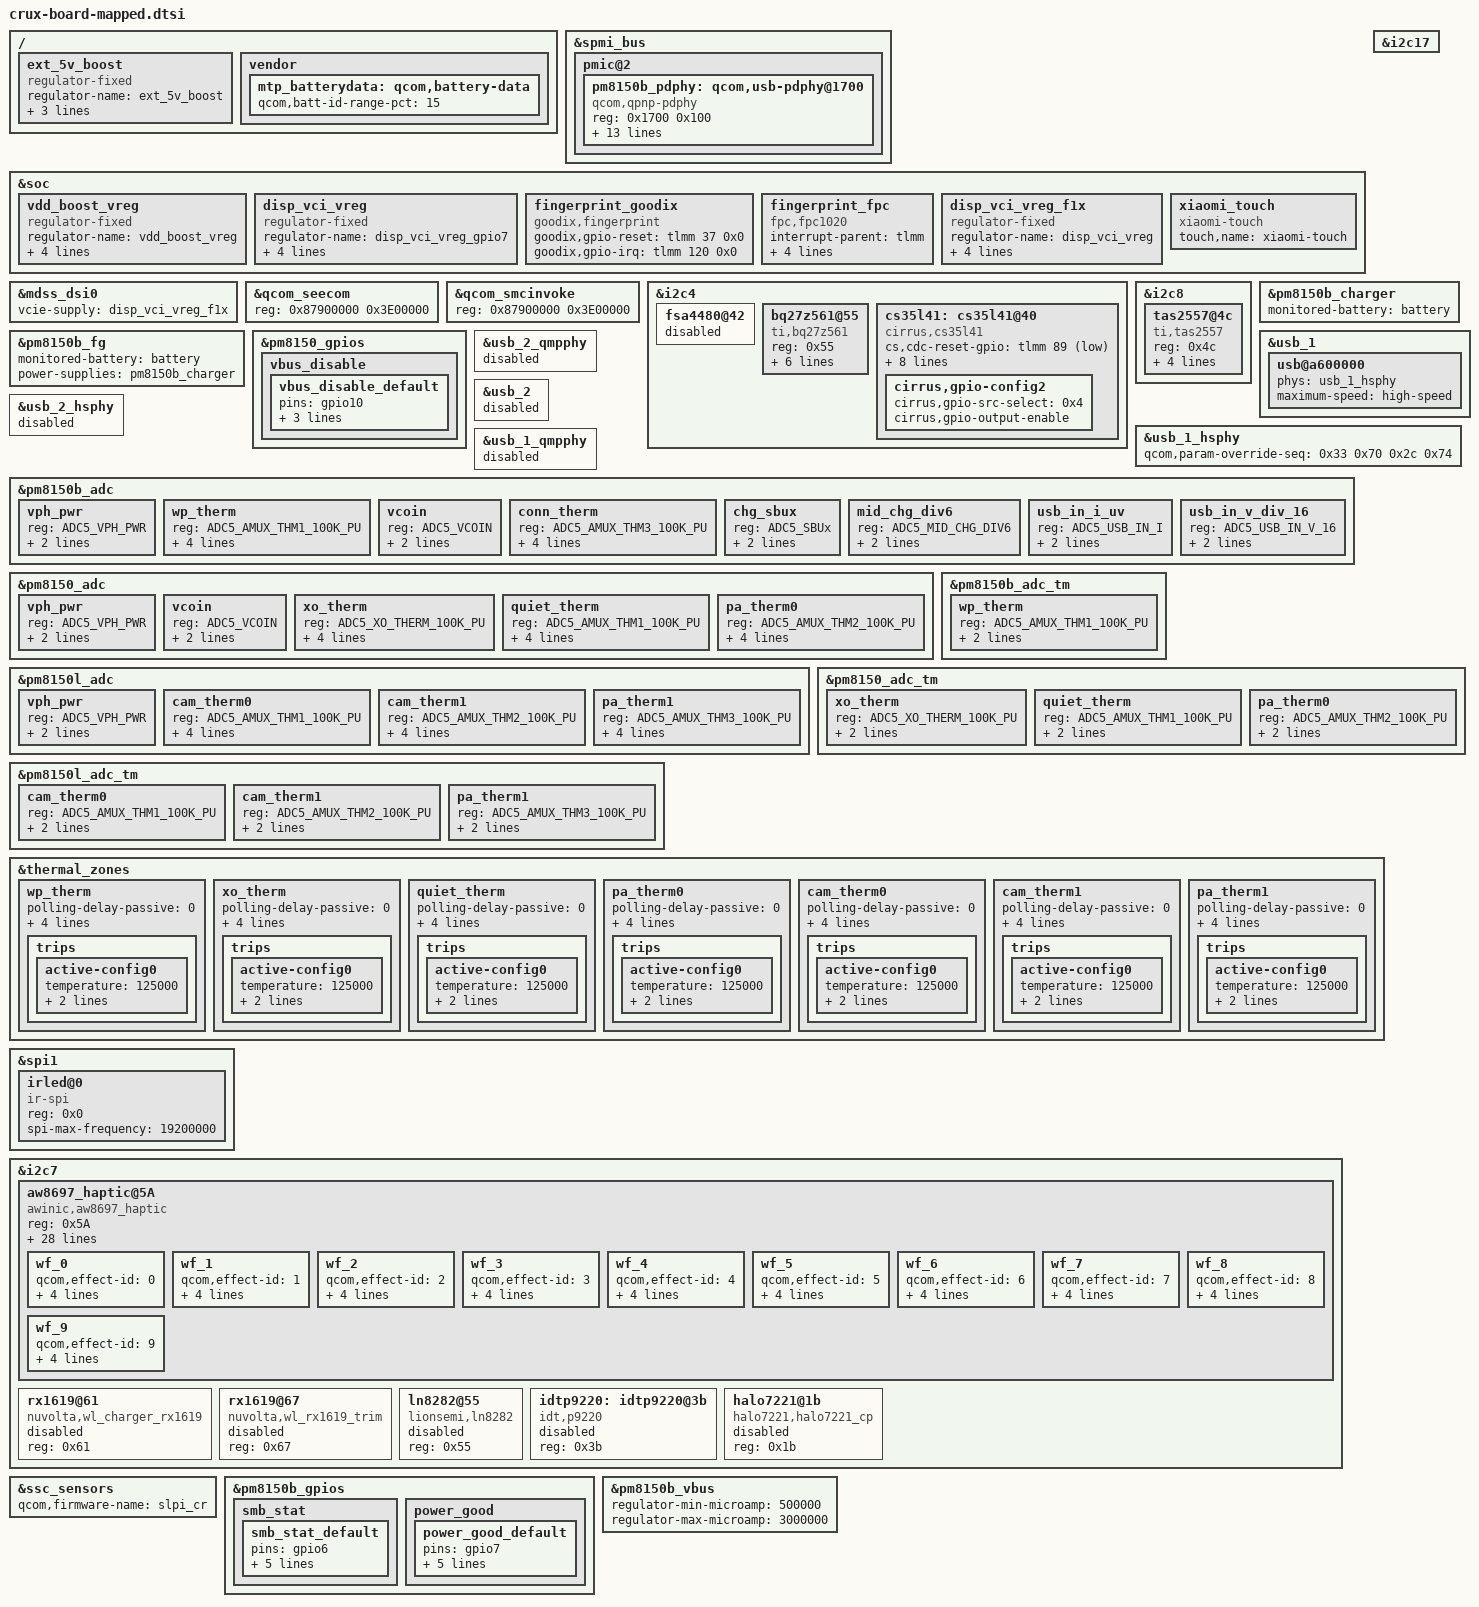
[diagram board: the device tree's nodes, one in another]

&spmi_bus {
	pmic@2 {
		pm8150b_pdphy: qcom,usb-pdphy@1700 {
		compatible = "qcom,qpnp-pdphy";
		reg = <0x1700 0x100>;
		vdd-pdphy-supply = <&vreg_l2a_3p1>;
		vbus-supply = <&pm8150b_vbus>;
		interrupts = <0x2 0x17 0x0 IRQ_TYPE_EDGE_RISING>,
			     <0x2 0x17 0x1 IRQ_TYPE_EDGE_RISING>,
			     <0x2 0x17 0x2 IRQ_TYPE_EDGE_RISING>,
			     <0x2 0x17 0x3 IRQ_TYPE_EDGE_RISING>,
			     <0x2 0x17 0x4 IRQ_TYPE_EDGE_RISING>,
			     <0x2 0x17 0x5 IRQ_TYPE_EDGE_RISING>,
			     <0x2 0x17 0x6 IRQ_TYPE_EDGE_RISING>,
			     <0x2 0x17 0x7 IRQ_TYPE_EDGE_RISING>;
		interrupt-names = "sig-tx",
				  "sig-rx",
				  "msg-tx",
				  "msg-rx",
				  "msg-tx-failed",
				  "msg-tx-discarded",
				  "msg-rx-discarded",
				  "fr-swap";
		qcom,default-sink-caps = <5000 3000>;
	};
};
};

/ {
	ext_5v_boost: ext_5v_boost {
		compatible = "regulator-fixed";
		regulator-name = "ext_5v_boost";
		gpio = <&pm8150b_gpios 12 GPIO_ACTIVE_HIGH>;
		enable-active-high;
		regulator-enable-ramp-delay = <1600>;
		status = "disabled";
	};
};




&soc {
	
	vdd_boost_vreg: vdd_boost_vreg {
		compatible = "regulator-fixed";
		regulator-name = "vdd_boost_vreg";
		startup-delay-us = <4000>;
		enable-active-high;
		regulator-always-on;
		gpio = <&pm8150b_gpios 5 0>;
	 };
	disp_vci_vreg: disp_vci_vreg {
		compatible = "regulator-fixed";
		regulator-name = "disp_vci_vreg_gpio7";
		start-delay-us = <4000>;
		enable-active-high;
		regulator-boot-on;
		gpio = <&tlmm 7 0>;
	};

	
	fingerprint_goodix {
		compatible = "goodix,fingerprint";
		goodix,gpio-reset = <&tlmm 37 0x0>;
		goodix,gpio-irq = <&tlmm 120 0x0>;
		/* fp-gpio-pwr = <&tlmm 125 0>; */
		status = "ok";
	};
	
	fingerprint_fpc {
		status = "ok";
		compatible = "fpc,fpc1020";
		interrupt-parent = <&tlmm>;
		interrupts = <118 0x0>;
		fpc,gpio_irq = <&tlmm 118 0x0>;
		/* fpc,enable-on-boot; */
		/* fpc,enable-wakeup;  */

		pinctrl-names = "fpc1020_reset_reset",
			"fpc1020_reset_active";

		pinctrl-0 = <&msm_gpio_119>;
		pinctrl-1 = <&msm_gpio_119_output_high>;
	};

	disp_vci_vreg_f1x: disp_vci_vreg_f1x {
		compatible = "regulator-fixed";
		regulator-name = "disp_vci_vreg";
		start-delay-us = <4000>;
		enable-active-high;
		regulator-boot-on;
		gpio = <&tlmm 21 0>;
	};
	xiaomi_touch {
		compatible = "xiaomi-touch";
		status = "ok";
		touch,name = "xiaomi-touch";
	};
	
};

&mdss_dsi0 {
	vcie-supply = <&disp_vci_vreg_f1x>;
};













&qcom_seecom {
	reg = <0x87900000 0x3E00000>;
};

&qcom_smcinvoke {
	reg = <0x87900000 0x3E00000>;
};

&i2c4 {
	status = "ok";

	fsa4480@42 {
		status = "disabled";
	};
};

&i2c8 {
	status = "ok";
	/*smart PA*/
	tas2557@4c{
		compatible = "ti,tas2557";
		reg = <0x4c>;
		ti,cdc-reset-gpio = <&tlmm 59 0>;
		ti,irq-gpio = <&tlmm 115 0>;
		ti,i2s-bits = <16>;
		ti,bypass-tmax = <0>;
	};
};

&i2c17 {
	status = "ok";
};

&pm8150b_fg {
	status = "okay";
	monitored-battery = <&battery>;
	power-supplies = <&pm8150b_charger>;
};

/ {
	vendor: vendor {

	mtp_batterydata: qcom,battery-data {
		qcom,batt-id-range-pct = <15>;
	};
	};
};


&pm8150_gpios {
	vbus_disable {
		vbus_disable_default: vbus_disable_default {
			pins = "gpio10";
			function = "normal";
			output-low;
			power-source = <1>;	/* 1.8V input supply */
		};
	};
};

&pm8150b_charger {
	status = "okay";
	monitored-battery = <&battery>;
};












&pm8150b_pdphy {
	vbus-supply = <&ext_5v_boost>;
	mi,pd_curr_limit = <1>;
	mi,pd_max_curr_limit = <3000000>;
};

&ext_5v_boost {
	status = "ok";
};



&usb_1 {
	usb@a600000 {
		phys = <&usb_1_hsphy>;
		phy-names = "usb2-phy";
		maximum-speed = "high-speed";
	};
};

&usb_1_hsphy {
	qcom,param-override-seq =
		<0x33 0x70
		 0x2c 0x74>;
};

&usb_2_qmpphy {
	status = "disabled";
};

&usb_2 {
        status = "disabled";
};

&usb_2_hsphy {
        status = "disabled";
};

&usb_1_qmpphy {
        status = "disabled";
};

&pm8150b_adc {
	vph_pwr {
		reg = <ADC5_VPH_PWR>;
		label = "vph_pwr";
		qcom,pre-scaling = <1 3>;
	};

	wp_therm {
		reg = <ADC5_AMUX_THM1_100K_PU>;
		label = "wp_therm";
		qcom,ratiometric;
		qcom,hw-settle-time = <200>;
		qcom,pre-scaling = <1 1>;
	};

	vcoin {
		reg = <ADC5_VCOIN>;
		label = "vcoin";
		qcom,pre-scaling = <1 3>;
	};

	conn_therm {
		reg = <ADC5_AMUX_THM3_100K_PU>;
		label = "conn_therm";
		qcom,ratiometric;
		qcom,hw-settle-time = <200>;
		qcom,pre-scaling = <1 1>;
	};

	chg_sbux {
		reg = <ADC5_SBUx>;
		label = "chg_sbux";
		qcom,pre-scaling = <1 3>;
	};

	mid_chg_div6 {
		reg = <ADC5_MID_CHG_DIV6>;
		label = "chg_mid";
		qcom,pre-scaling = <1 6>;
	};

	usb_in_i_uv {
		reg = <ADC5_USB_IN_I>;
		label = "usb_in_i_uv";
		qcom,pre-scaling = <1 1>;
	};

	usb_in_v_div_16 {
		reg = <ADC5_USB_IN_V_16>;
		label = "usb_in_v_div_16";
		qcom,pre-scaling = <1 16>;
	};
};

&pm8150_adc {
	vph_pwr {
		reg = <ADC5_VPH_PWR>;
		label = "vph_pwr";
		qcom,pre-scaling = <1 3>;
	};

	vcoin {
		reg = <ADC5_VCOIN>;
		label = "vcoin";
		qcom,pre-scaling = <1 3>;
	};

	xo_therm {
		reg = <ADC5_XO_THERM_100K_PU>;
		label = "xo_therm";
		qcom,ratiometric;
		qcom,hw-settle-time = <200>;
		qcom,pre-scaling = <1 1>;
	};

	quiet_therm {
		reg = <ADC5_AMUX_THM1_100K_PU>;
		label = "quiet_therm";
		qcom,ratiometric;
		qcom,hw-settle-time = <200>;
		qcom,pre-scaling = <1 1>;
	};

	pa_therm0 {
		reg = <ADC5_AMUX_THM2_100K_PU>;
		label = "pa_therm0";
		qcom,ratiometric;
		qcom,hw-settle-time = <200>;
		qcom,pre-scaling = <1 1>;
	};
};

&pm8150l_adc {
	vph_pwr {
		reg = <ADC5_VPH_PWR>;
		label = "vph_pwr";
		qcom,pre-scaling = <1 3>;
	};

	cam_therm0 {
		reg = <ADC5_AMUX_THM1_100K_PU>;
		label = "cam_therm0";
		qcom,ratiometric;
		qcom,hw-settle-time = <200>;
		qcom,pre-scaling = <1 1>;
	};

	cam_therm1 {
		reg = <ADC5_AMUX_THM2_100K_PU>;
		label = "cam_therm1";
		qcom,ratiometric;
		qcom,hw-settle-time = <200>;
		qcom,pre-scaling = <1 1>;
	};

	pa_therm1 {
		reg = <ADC5_AMUX_THM3_100K_PU>;
		label = "pa_therm1";
		qcom,ratiometric;
		qcom,hw-settle-time = <200>;
		qcom,pre-scaling = <1 1>;
	};
};

&pm8150b_adc_tm {
	wp_therm {
		reg = <ADC5_AMUX_THM1_100K_PU>;
		qcom,ratiometric;
		qcom,hw-settle-time = <200>;
	};
};

&pm8150_adc_tm {
	xo_therm {
		reg = <ADC5_XO_THERM_100K_PU>;
		qcom,ratiometric;
		qcom,hw-settle-time = <200>;
	};
        quiet_therm {
                reg = <ADC5_AMUX_THM1_100K_PU>;
                qcom,ratiometric;
                qcom,hw-settle-time = <200>;
        };

        pa_therm0 {
                reg = <ADC5_AMUX_THM2_100K_PU>;
                qcom,ratiometric;
                qcom,hw-settle-time = <200>;
        };
};

&pm8150l_adc_tm {
	cam_therm0 {
		reg = <ADC5_AMUX_THM1_100K_PU>;
		qcom,ratiometric;
		qcom,hw-settle-time = <200>;
	};

	cam_therm1 {
		reg = <ADC5_AMUX_THM2_100K_PU>;
		qcom,ratiometric;
		qcom,hw-settle-time = <200>;
	};

	pa_therm1 {
		reg = <ADC5_AMUX_THM3_100K_PU>;
		qcom,ratiometric;
		qcom,hw-settle-time = <200>;
	};
};

&thermal_zones {
	wp_therm {
		polling-delay-passive = <0>;
		polling-delay = <0>;
		thermal-governor = "user_space";
		thermal-sensors = <&pm8150b_adc_tm ADC5_AMUX_THM1_100K_PU>;
		trips {
			active-config0 {
				temperature = <125000>;
				hysteresis = <1000>;
				type = "passive";
			};
		};
	};

	xo_therm {
		polling-delay-passive = <0>;
		polling-delay = <0>;
		thermal-governor = "user_space";
		thermal-sensors = <&pm8150_adc_tm ADC5_XO_THERM_100K_PU>;
		trips {
			active-config0 {
				temperature = <125000>;
				hysteresis = <1000>;
				type = "passive";
			};
		};
	};

        quiet_therm {
                polling-delay-passive = <0>;
                polling-delay = <0>;
                thermal-governor = "user_space";
                thermal-sensors = <&pm8150_adc_tm ADC5_AMUX_THM1_100K_PU>;
                trips {
                       active-config0 {
                               temperature = <125000>;
                               hysteresis = <1000>;
                               type = "passive";
                       };
                };
        };

        pa_therm0 {
                polling-delay-passive = <0>;
                polling-delay = <0>;
                thermal-governor = "user_space";
                thermal-sensors = <&pm8150_adc_tm ADC5_AMUX_THM2_100K_PU>;
                trips {
                       active-config0 {
                               temperature = <125000>;
                               hysteresis = <1000>;
                               type = "passive";
                       };
                };
        };

	cam_therm0 {
		polling-delay-passive = <0>;
		polling-delay = <0>;
		thermal-governor = "user_space";
		thermal-sensors = <&pm8150l_adc_tm ADC5_AMUX_THM1_100K_PU>;
		trips {
			active-config0 {
				temperature = <125000>;
				hysteresis = <1000>;
				type = "passive";
			};
		};
	};

	cam_therm1 {
		polling-delay-passive = <0>;
		polling-delay = <0>;
		thermal-governor = "user_space";
		thermal-sensors = <&pm8150l_adc_tm ADC5_AMUX_THM2_100K_PU>;
		trips {
			active-config0 {
				temperature = <125000>;
				hysteresis = <1000>;
				type = "passive";
			};
		};
	};

	pa_therm1 {
		polling-delay-passive = <0>;
		polling-delay = <0>;
		thermal-governor = "user_space";
		thermal-sensors = <&pm8150l_adc_tm ADC5_AMUX_THM3_100K_PU>;
		trips {
			active-config0 {
				temperature = <125000>;
				hysteresis = <1000>;
				type = "passive";
			};
		};
	};
};

&i2c4 {
	status = "ok";
	bq27z561@55 {
		compatible = "ti,bq27z561";
		reg = <0x55>;
		bq,charge-full-design = <4000000>;
		bq,recharge-voltage   = <4380>;
		bq,soc_decimal_rate = <
			0  38
			10 35
			20 33
			30 33
			40 33
			50 33
			60 33
			70 30
			80 25
			90 20
			95 10
			99  5 >;
		bq,cold_thermal_seq = <
			1      0  100 1700
			2  (-300)   0 1000 >;
	};

	fsa4480@42 {
		status = "disabled";
	};

	cs35l41: cs35l41@40 {
		#sound-dai-cells = <1>;
		compatible = "cirrus,cs35l41";
		cs,cdc-reset-gpio = <&tlmm 89 0x01>;
		reg = <0x40>;
		pinctrl-names = "cs35l41_irq_default";
		pinctrl-0 = <&cs35l41_int_default>;
		interrupt-parent = <&tlmm>;
		interrupts = <10 8>;

		cirrus,temp-warn_threshold = <3>;
		cirrus,boost-peak-milliamp = <4000>;
		cirrus,boost-ind-nanohenry = <1000>;
		cirrus,boost-cap-microfarad = <15>;
		cirrus,gpio-config2 {
			cirrus,gpio-src-select = <0x4>;
			cirrus,gpio-output-enable;
		};
		/*
		VA-supply = <&dummy_vreg>;
		VP-supply = <&dummy_vreg>;
		interrupt-parent = <&tlmm>;
		interrupts = <11 8>;
		reset-gpios = <&tlmm 7 0x01>;
		VA-supply = <&pm8998_s4>;
		VP-supply = <&audio_vsys>;
		cirrus,boost-peak-milliamp = <4500>;
		cirrus,boost-ind-nanohenry = <1000>;
		cirrus,boost-cap-microfarad = <15>;
		cirrus,gpio-config2 {
			cirrus,gpio-src-select = <0x4>;
			cirrus,gpio-output-enable;
		};
		*/
	};
};


&spi1 {
	status = "ok";
	irled@0 {
		compatible = "ir-spi";
		reg = <0x0>;
		status = "ok";
		spi-max-frequency = <19200000>;
	};
};

&i2c7 {
	status = "ok";
	aw8697_haptic@5A {
		compatible = "awinic,aw8697_haptic";
		reg = <0x5A>;
		reset-gpio = <&tlmm 6 0>;
		irq-gpio = <&tlmm 27 0>;
		vib_mode = < 0 >;   /*mode:   RAM mode->0; CONT mode -> 1*/
		vib_f0_pre = < 1700 >;
		vib_f0_cali_percen = < 7 >;
		vib_cont_drv_lev = < 88 >;
		vib_cont_drv_lvl_ov = < 88 >;
		vib_cont_td = < 0xf06c >;
		vib_cont_zc_thr = < 0x08f8 >;  /*hq 0x08F8 */
		vib_cont_num_brk = < 3 >;
		vib_f0_coeff = < 260 >; /*Don't modify it    2.604167*/
		vib_f0_trace_parameter = < 9 3 1 31 >;
		vib_bemf_config = < 0 0x08 0x03 0xf8 >;
		vib_sw_brake = < 0x2c >;
		vib_tset = < 0x12 >;
		vib_r_spare = < 0x68 >;
		vib_bstdbg = < 0x30 0xeb 0xd4 0 0 0 >;
		vib_effect_id_boundary = < 10 >;
		vib_effect_max = < 170 >;
		vib_trig_config = < 0 1 0 1 2
						0 1 0 1 2
						0 1 0 1 2 >;
		vib_bst_vol_default = < 0x1b >;
		vib_bst_vol_ram = < 0x1b >;
		vib_bst_vol_rtp = < 0x16 >;
		vib_rtp_time = < 20 20 20 20 20 20 20 20 20000 15000
				 15000 20000 25000 15000 30000 25000 20000 20000 20000 20000
				 20000 20000 20000 20000 20000 20000 20000 20000 20000 20000
				 20000 20000 20000 20000 20000 20000 20000 20000 20000 20000
				 20000 20000 20000 20000 20000 20000 20000 20000 20000 20000
				 20000 20000 20000 20000 20000 20000 20000 20000 20000 20000
				 20000 20000 20000 20000 20000 20000 20000 20000 20000 20000
				 20000 20000 20000 20000 20000 20000 20000 20000 20000 20000
				 20000 20000 20000 20000 20000 20000 20000 20000 20000 20000
				 20000 20000 20000 20000 20000 20000 20000 20000 20000 20000
				 20000 20000 20000 20000 20000 20000 20000 20000 20000 20000
				 20000 20000 20000 20000 20000 20000 20000 20000 20000 20000
				 20000 20000 20000 20000 20000 20000 20000 20000 20000 20000
				 20000 20000 20000 20000 20000 20000 20000 20000 20000 20000
				 20000 20000 20000 20000 20000 20000 20000 20000 20000 20000
				 20000 20000 20000 20000 20000 20000 20000 20000 20000 20000
				 20000 20000 20000 20000 20000 20000 20000 20000 20000 20000
				 20000 20000 20000 20000 20000 >;
		pinctrl-names = "aw8697_reset_reset","aw8697_reset_active","aw8697_interrupt_active";
		pinctrl-0 = <&msm_gpio_6>;
		pinctrl-1 = <&msm_gpio_6_output_high>;
		pinctrl-2 = <&msm_gpio_27>;
		status = "ok";
		wf_0 {
			/*CLICK*/
			qcom,effect-id = <0>;
			qcom,wf-vmax-mv = <3600>;
			qcom,wf-pattern = [3e 3e];
			qcom,wf-brake-pattern = [02 01 00 00];
			qcom,wf-play-rate-us = <20000>;
		};
		wf_1 {
			/*DOUBLE CLICK*/
			qcom,effect-id = <1>;
			qcom,wf-vmax-mv = <3600>;
			qcom,wf-pattern = [7e 3e];
			qcom,wf-brake-pattern = [03 01 00 00];
			qcom,wf-play-rate-us = <20000>;
		};
		wf_2 {
			/*TICK*/
			qcom,effect-id = <2>;
			qcom,wf-vmax-mv = <3600>;
			qcom,wf-pattern = [7e 3e];
			qcom,wf-brake-pattern = [02 01 00 00];
			qcom,wf-play-rate-us = <20000>;
		};
		wf_3 {
			/*THUD*/
			qcom,effect-id = <3>;
			qcom,wf-vmax-mv = <3600>;
			qcom,wf-pattern = [3e 3e];
			qcom,wf-brake-pattern = [02 01 00 00];
			qcom,wf-play-rate-us = <20000>;
		};
		wf_4 {
			/*POP*/
			qcom,effect-id = <4>;
			qcom,wf-vmax-mv = <3600>;
			qcom,wf-pattern = [3e 3e];
			qcom,wf-brake-pattern = [02 01 00 00];
			qcom,wf-play-rate-us = <28000>;
		};
		wf_5 {
			/*HEAVY CLICK*/
			qcom,effect-id = <5>;
			qcom,wf-vmax-mv = <3600>;
			qcom,wf-pattern = [7e 7e 7e];
			qcom,wf-brake-pattern = [03 03 01 00];
			qcom,wf-play-rate-us = <20000>;
		};
		wf_6 {
			/*id 6*/
			qcom,effect-id = <6>;
			qcom,wf-vmax-mv = <3600>;
			qcom,wf-pattern = [3e 3e];
			qcom,wf-brake-pattern = [02 01 00 00];
			qcom,wf-play-rate-us = <20000>;
		};
		wf_7 {
			/*id 7*/
			qcom,effect-id = <7>;
			qcom,wf-vmax-mv = <3600>;
			qcom,wf-pattern = [3e 3e];
			qcom,wf-brake-pattern = [02 01 00 00];
			qcom,wf-play-rate-us = <20000>;
		};
		wf_8 {
			/*id 8*/
			qcom,effect-id = <8>;
			qcom,wf-vmax-mv = <3600>;
			qcom,wf-pattern = [3e 3e];
			qcom,wf-brake-pattern = [02 01 00 00];
			qcom,wf-play-rate-us = <20000>;
		};
		wf_9 {
			/*id 9*/
			qcom,effect-id = <9>;
			qcom,wf-vmax-mv = <3600>;
			qcom,wf-pattern = [3e 3e];
			qcom,wf-brake-pattern = [02 01 00 00];
			qcom,wf-play-rate-us = <20000>;
		};
	};

	rx1619@61 {
		/* [crux 2026-09-25] 本机无线充硬件不存在：只留骨架与禁用，其余参数（gpio/pinctrl/各家自定义）已删 */
		status = "disabled";
		compatible = "nuvolta,wl_charger_rx1619";
		reg = <0x61>;
	};
	rx1619@67 {
		/* [crux 2026-09-25] 本机无线充硬件不存在：只留骨架与禁用，其余参数（gpio/pinctrl/各家自定义）已删 */
		status = "disabled";
		compatible = "nuvolta,wl_rx1619_trim";
		reg = <0x67>;
	};
	ln8282@55 {
		/* [crux 2026-09-25] 本机无线充硬件不存在：只留骨架与禁用，其余参数（gpio/pinctrl/各家自定义）已删 */
		status = "disabled";
		compatible = "lionsemi,ln8282";
		reg = <0x55>;
	};
	idtp9220: idtp9220@3b {
		/* [crux 2026-09-25] 本机无线充硬件不存在：只留骨架与禁用，其余参数（gpio/pinctrl/各家自定义）已删 */
		status = "disabled";
		compatible = "idt,p9220";
		reg = <0x3b>;
	};
	halo7221@1b {
		/* [crux 2026-09-25] 本机无线充硬件不存在：只留骨架与禁用，其余参数（gpio/pinctrl/各家自定义）已删 */
		status = "disabled";
		compatible = "halo7221,halo7221_cp";
		reg = <0x1b>;
	};
};

&ssc_sensors {
	qcom,firmware-name = "slpi_cr";
};




&pm8150b_gpios {
		smb_stat {
			smb_stat_default: smb_stat_default {
				pins = "gpio6";
				function = "normal";
				input-enable;
				bias-pull-up;
				qcom,pull-up-strength = <PMIC_GPIO_PULL_UP_30>;
				power-source = <0>;
			};
		};
		power_good {
			/*Get the DC Power Good signal*/
			power_good_default: power_good_default {
				pins = "gpio7";
				function = "normal";
				qcom,drive-strength = <2>; /* 2 MA */
				bias-disable;         /* NO pull */
				power-source = <1>;
				input-enable;
			};
		};
};

&pm8150b_vbus {
	regulator-min-microamp = <500000>;
	regulator-max-microamp = <3000000>;
	status = "okay";
};
